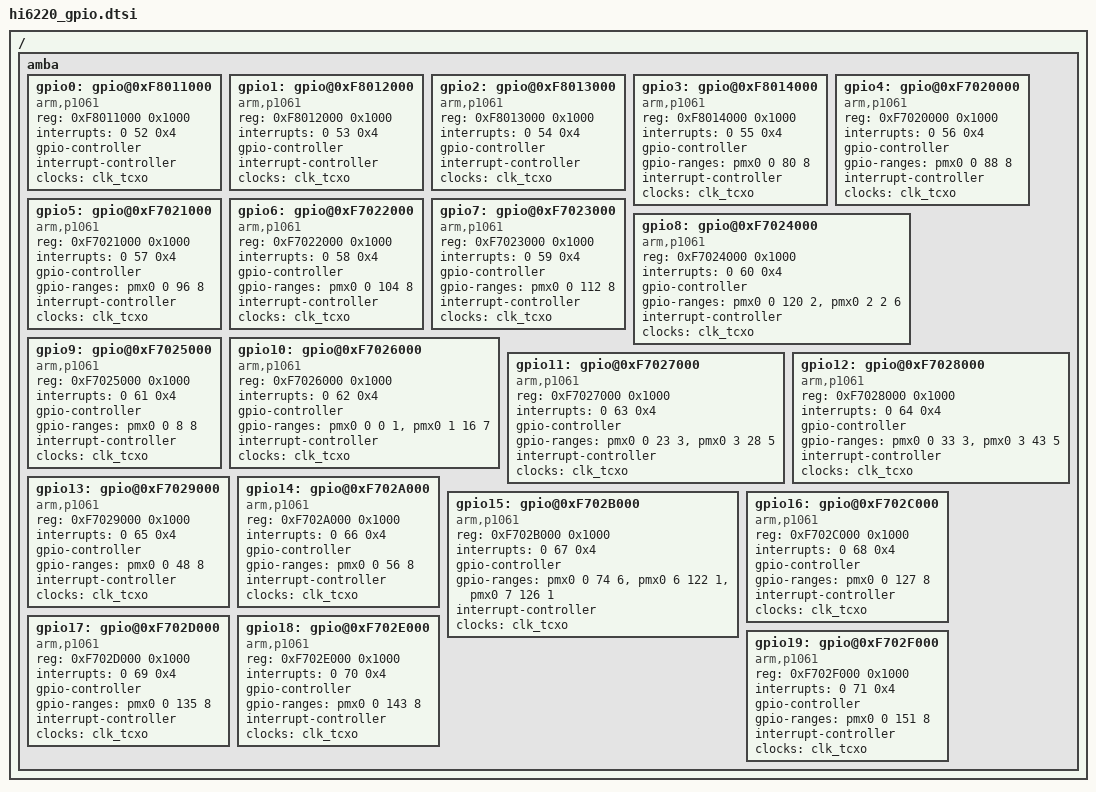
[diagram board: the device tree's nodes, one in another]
/*****************************************
Generated Time : 2014-07-16-17-14
Author         : s00249479
Tool Version   : V1.0
*****************************************/
/ {
    amba{
        gpio0: gpio@0xF8011000 {
            compatible = "arm,p1061", "arm,primecell";
            reg = <0xF8011000 0x1000>;
            interrupts = <0 52 0x4>;
            gpio-controller;
            #gpio-cells = <2>;
            interrupt-controller;
            #interrupt-cells = <2>;
            clocks = <&clk_tcxo>;
            clock-names = "apb_pclk";
            status = "ok";
        };

        gpio1: gpio@0xF8012000 {
            compatible = "arm,p1061", "arm,primecell";
            reg = <0xF8012000 0x1000>;
            interrupts = <0 53 0x4>;
            gpio-controller;
            #gpio-cells = <2>;
            interrupt-controller;
            #interrupt-cells = <2>;
            clocks = <&clk_tcxo>;
            clock-names = "apb_pclk";
            status = "ok";
        };

        gpio2: gpio@0xF8013000 {
            compatible = "arm,p1061", "arm,primecell";
            reg = <0xF8013000 0x1000>;
            interrupts = <0 54 0x4>;
            gpio-controller;
            #gpio-cells = <2>;
            interrupt-controller;
            #interrupt-cells = <2>;
            clocks = <&clk_tcxo>;
            clock-names = "apb_pclk";
            status = "ok";
        };

        gpio3: gpio@0xF8014000 {
            compatible = "arm,p1061", "arm,primecell";
            reg = <0xF8014000 0x1000>;
            interrupts = <0 55 0x4>;
            gpio-controller;
            #gpio-cells = <2>;
            gpio-ranges = <&pmx0 0 80 8>;
            interrupt-controller;
            #interrupt-cells = <2>;
            clocks = <&clk_tcxo>;
            clock-names = "apb_pclk";
            status = "ok";
        };

        gpio4: gpio@0xF7020000 {
            compatible = "arm,p1061", "arm,primecell";
            reg = <0xF7020000 0x1000>;
            interrupts = <0 56 0x4>;
            gpio-controller;
            #gpio-cells = <2>;
            gpio-ranges = <&pmx0 0 88 8>;
            interrupt-controller;
            #interrupt-cells = <2>;
            clocks = <&clk_tcxo>;
            clock-names = "apb_pclk";
            status = "ok";
        };

        gpio5: gpio@0xF7021000 {
            compatible = "arm,p1061", "arm,primecell";
            reg = <0xF7021000 0x1000>;
            interrupts = <0 57 0x4>;
            gpio-controller;
            #gpio-cells = <2>;
            gpio-ranges = <&pmx0 0 96 8>;
            interrupt-controller;
            #interrupt-cells = <2>;
            clocks = <&clk_tcxo>;
            clock-names = "apb_pclk";
            status = "ok";
        };

        gpio6: gpio@0xF7022000 {
            compatible = "arm,p1061", "arm,primecell";
            reg = <0xF7022000 0x1000>;
            interrupts = <0 58 0x4>;
            gpio-controller;
            #gpio-cells = <2>;
            gpio-ranges = <&pmx0 0 104 8>;
            interrupt-controller;
            #interrupt-cells = <2>;
            clocks = <&clk_tcxo>;
            clock-names = "apb_pclk";
            status = "ok";
        };

        gpio7: gpio@0xF7023000 {
            compatible = "arm,p1061", "arm,primecell";
            reg = <0xF7023000 0x1000>;
            interrupts = <0 59 0x4>;
            gpio-controller;
            #gpio-cells = <2>;
            gpio-ranges = <&pmx0 0 112 8>;
            interrupt-controller;
            #interrupt-cells = <2>;
            clocks = <&clk_tcxo>;
            clock-names = "apb_pclk";
            status = "ok";
        };

        gpio8: gpio@0xF7024000 {
            compatible = "arm,p1061", "arm,primecell";
            reg = <0xF7024000 0x1000>;
            interrupts = <0 60 0x4>;
            gpio-controller;
            #gpio-cells = <2>;
            gpio-ranges = <&pmx0 0 120 2 &pmx0 2 2 6>;
            interrupt-controller;
            #interrupt-cells = <2>;
            clocks = <&clk_tcxo>;
            clock-names = "apb_pclk";
            status = "ok";
        };

        gpio9: gpio@0xF7025000 {
            compatible = "arm,p1061", "arm,primecell";
            reg = <0xF7025000 0x1000>;
            interrupts = <0 61 0x4>;
            gpio-controller;
            #gpio-cells = <2>;
            gpio-ranges = <&pmx0 0 8 8>;
            interrupt-controller;
            #interrupt-cells = <2>;
            clocks = <&clk_tcxo>;
            clock-names = "apb_pclk";
            status = "ok";
        };

        gpio10: gpio@0xF7026000 {
            compatible = "arm,p1061", "arm,primecell";
            reg = <0xF7026000 0x1000>;
            interrupts = <0 62 0x4>;
            gpio-controller;
            #gpio-cells = <2>;
            gpio-ranges = <&pmx0 0 0 1 &pmx0 1 16 7>;
            interrupt-controller;
            #interrupt-cells = <2>;
            clocks = <&clk_tcxo>;
            clock-names = "apb_pclk";
            status = "ok";
        };

        gpio11: gpio@0xF7027000 {
            compatible = "arm,p1061", "arm,primecell";
            reg = <0xF7027000 0x1000>;
            interrupts = <0 63 0x4>;
            gpio-controller;
            #gpio-cells = <2>;
            gpio-ranges = <&pmx0 0 23 3 &pmx0 3 28 5>;
            interrupt-controller;
            #interrupt-cells = <2>;
            clocks = <&clk_tcxo>;
            clock-names = "apb_pclk";
            status = "ok";
        };

        gpio12: gpio@0xF7028000 {
            compatible = "arm,p1061", "arm,primecell";
            reg = <0xF7028000 0x1000>;
            interrupts = <0 64 0x4>;
            gpio-controller;
            #gpio-cells = <2>;
            gpio-ranges = <&pmx0 0 33 3 &pmx0 3 43 5>;
            interrupt-controller;
            #interrupt-cells = <2>;
            clocks = <&clk_tcxo>;
            clock-names = "apb_pclk";
            status = "ok";
        };

        gpio13: gpio@0xF7029000 {
            compatible = "arm,p1061", "arm,primecell";
            reg = <0xF7029000 0x1000>;
            interrupts = <0 65 0x4>;
            gpio-controller;
            #gpio-cells = <2>;
            gpio-ranges = <&pmx0 0 48 8>;
            interrupt-controller;
            #interrupt-cells = <2>;
            clocks = <&clk_tcxo>;
            clock-names = "apb_pclk";
            status = "ok";
        };

        gpio14: gpio@0xF702A000 {
            compatible = "arm,p1061", "arm,primecell";
            reg = <0xF702A000 0x1000>;
            interrupts = <0 66 0x4>;
            gpio-controller;
            #gpio-cells = <2>;
            gpio-ranges = <&pmx0 0 56 8>;
            interrupt-controller;
            #interrupt-cells = <2>;
            clocks = <&clk_tcxo>;
            clock-names = "apb_pclk";
            status = "ok";
        };

        gpio15: gpio@0xF702B000 {
            compatible = "arm,p1061", "arm,primecell";
            reg = <0xF702B000 0x1000>;
            interrupts = <0 67 0x4>;
            gpio-controller;
            #gpio-cells = <2>;
            gpio-ranges = <&pmx0 0 74 6 &pmx0 6 122 1 &pmx0 7 126 1>;
            interrupt-controller;
            #interrupt-cells = <2>;
            clocks = <&clk_tcxo>;
            clock-names = "apb_pclk";
            status = "ok";
        };

        gpio16: gpio@0xF702C000 {
            compatible = "arm,p1061", "arm,primecell";
            reg = <0xF702C000 0x1000>;
            interrupts = <0 68 0x4>;
            gpio-controller;
            #gpio-cells = <2>;
            gpio-ranges = <&pmx0 0 127 8>;
            interrupt-controller;
            #interrupt-cells = <2>;
            clocks = <&clk_tcxo>;
            clock-names = "apb_pclk";
            status = "ok";
        };

        gpio17: gpio@0xF702D000 {
            compatible = "arm,p1061", "arm,primecell";
            reg = <0xF702D000 0x1000>;
            interrupts = <0 69 0x4>;
            gpio-controller;
            #gpio-cells = <2>;
            gpio-ranges = <&pmx0 0 135 8>;
            interrupt-controller;
            #interrupt-cells = <2>;
            clocks = <&clk_tcxo>;
            clock-names = "apb_pclk";
            status = "ok";
        };

        gpio18: gpio@0xF702E000 {
            compatible = "arm,p1061", "arm,primecell";
            reg = <0xF702E000 0x1000>;
            interrupts = <0 70 0x4>;
            gpio-controller;
            #gpio-cells = <2>;
            gpio-ranges = <&pmx0 0 143 8>;
            interrupt-controller;
            #interrupt-cells = <2>;
            clocks = <&clk_tcxo>;
            clock-names = "apb_pclk";
            status = "ok";
        };

        gpio19: gpio@0xF702F000 {
            compatible = "arm,p1061", "arm,primecell";
            reg = <0xF702F000 0x1000>;
            interrupts = <0 71 0x4>;
            gpio-controller;
            #gpio-cells = <2>;
            gpio-ranges = <&pmx0 0 151 8>;
            interrupt-controller;
            #interrupt-cells = <2>;
            clocks = <&clk_tcxo>;
            clock-names = "apb_pclk";
            status = "ok";
        };

    };
};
